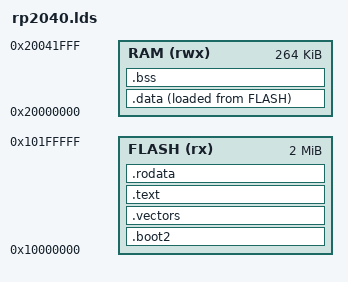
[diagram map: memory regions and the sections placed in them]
/* RP2040 bare-metal link map (Cortex-M0+, no SDK).
 *
 * Flash (XIP) at 0x10000000: the 256-byte checksummed second stage (.boot2,
 * generated by tools/pad_checksum.g) sits first, then the vector table at
 * 0x10000100 -- the address the bootrom's stage-2 hands control to -- then
 * code/rodata. .data is loaded from flash and copied to SRAM by reset_handler
 * (crt0 in rp2040.c); .bss is zeroed there. The stack lives at the top of the
 * 264 KB main SRAM. Mirrors the freestanding arch/<arch>/*.lds, including the
 * contiguous gwen_data_vt sentinel block that g_typ() indexes into. */

OUTPUT_FORMAT("elf32-littlearm")
ENTRY(reset_handler)

MEMORY {
  FLASH (rx) : ORIGIN = 0x10000000, LENGTH = 2048k
  RAM  (rwx) : ORIGIN = 0x20000000, LENGTH = 264k
}

SECTIONS {
  /* 256-byte checksummed boot2 at flash base. */
  .boot2 : { KEEP(*(.boot2)) } > FLASH
  ASSERT(SIZEOF(.boot2) == 256, "boot2 must be exactly 256 bytes")

  /* Vector table at 0x10000100 (immediately after boot2). */
  .vectors : { KEEP(*(.vectors)) } > FLASH

  .text : {
    *(.text .text.*)
    /* gwen data self-quote sentinels: kept contiguous and in enum order
       (gwen_data_vt.NN) so g_typ() recovers a kind from an ap's slot index.
       Mirrors vt.ld for the host link. */
    . = ALIGN(16);
    __start_gwen_data_vt = .;
    KEEP(*(SORT_BY_NAME(gwen_data_vt.*)))
    __stop_gwen_data_vt = .;
  } > FLASH

  .rodata : {
    *(.rodata .rodata.*)
    *(.srodata .srodata.*)
  } > FLASH

  /* .data: VMA in SRAM, LMA in flash. reset_handler copies it. */
  . = ALIGN(4);
  .data : {
    __data_start__ = .;
    *(.data .data.*)
    *(.sdata .sdata.*)
    . = ALIGN(4);
    __data_end__ = .;
  } > RAM AT> FLASH
  __data_load__ = LOADADDR(.data);

  .bss (NOLOAD) : {
    . = ALIGN(4);
    __bss_start__ = .;
    *(.bss .bss.*)
    *(.sbss .sbss.*)
    *(COMMON)
    . = ALIGN(4);
    __bss_end__ = .;
  } > RAM

  __stack_top__ = ORIGIN(RAM) + LENGTH(RAM);

  /DISCARD/ : {
    *(.eh_frame*)
    *(.note .note.*)
    *(.ARM.exidx*)
    *(.ARM.attributes)
  }
}
